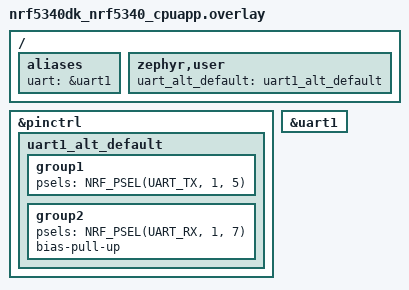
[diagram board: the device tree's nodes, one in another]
/*
 * Copyright (c) 2025 Nordic Semiconductor ASA
 * SPDX-License-Identifier: Apache-2.0
 */

/ {
	aliases {
		uart = &uart1;
	};

	zephyr,user {
		uart_alt_default = <&uart1_alt_default>;
	};
};

&pinctrl {
	/* Alternative pin configuration for UART1 */
	uart1_alt_default: uart1_alt_default {
		group1 {
			psels = <NRF_PSEL(UART_TX, 1, 5)>;
		};
		group2 {
			psels = <NRF_PSEL(UART_RX, 1, 7)>;
			bias-pull-up;
		};
	};
};

&uart1 {
	status = "okay";
};
